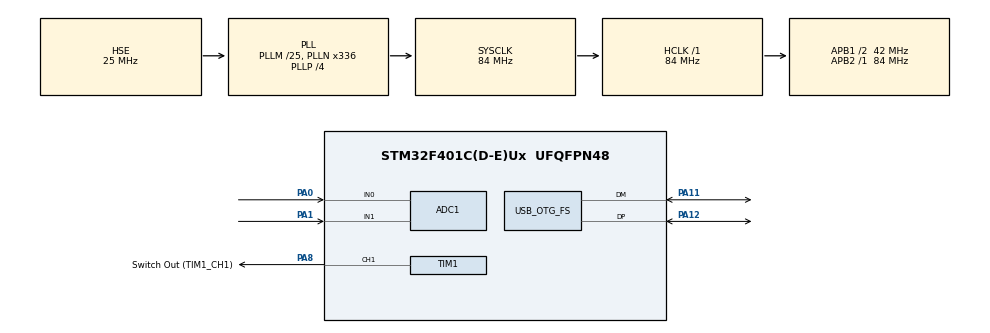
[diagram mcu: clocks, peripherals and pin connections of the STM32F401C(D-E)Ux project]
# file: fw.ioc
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ADC1.Channel-1\#ChannelRegularConversion=ADC_CHANNEL_0
ADC1.Channel-5\#ChannelRegularConversion=ADC_CHANNEL_1
ADC1.ContinuousConvMode=DISABLE
ADC1.DMAContinuousRequests=ENABLE
ADC1.DiscontinuousConvMode=DISABLE
ADC1.EOCSelection=ADC_EOC_SINGLE_CONV
ADC1.ExternalTrigConv=ADC_EXTERNALTRIGCONV_T1_CC3
ADC1.InjNumberOfConversion=0
ADC1.NbrOfConversion=2
ADC1.NbrOfConversionFlag=1
ADC1.Rank-1\#ChannelRegularConversion=1
ADC1.Rank-5\#ChannelRegularConversion=2
ADC1.SamplingTime-1\#ChannelRegularConversion=ADC_SAMPLETIME_3CYCLES
ADC1.SamplingTime-5\#ChannelRegularConversion=ADC_SAMPLETIME_3CYCLES
ADC1.master=1
Dma.ADC1.0.Direction=DMA_PERIPH_TO_MEMORY
Dma.ADC1.0.FIFOMode=DMA_FIFOMODE_DISABLE
Dma.ADC1.0.Instance=DMA2_Stream0
Dma.ADC1.0.MemDataAlignment=DMA_MDATAALIGN_HALFWORD
Dma.ADC1.0.MemInc=DMA_MINC_ENABLE
Dma.ADC1.0.Mode=DMA_CIRCULAR
Dma.ADC1.0.PeriphDataAlignment=DMA_PDATAALIGN_HALFWORD
Dma.ADC1.0.PeriphInc=DMA_PINC_DISABLE
Dma.ADC1.0.Priority=DMA_PRIORITY_LOW
Dma.Request0=ADC1
Mcu.Family=STM32F4
Mcu.Name=STM32F401C(D-E)Ux
Mcu.Package=UFQFPN48
NVIC.DMA2_Stream0_IRQn=true\:0\:0\:false\:false\:true\:false\:true\:true
NVIC.OTG_FS_IRQn=true\:0\:0\:false\:false\:true\:false\:true\:true
NVIC.PriorityGroup=NVIC_PRIORITYGROUP_4
NVIC.TIM1_BRK_TIM9_IRQn=true\:0\:0\:false\:false\:true\:true\:false\:true
NVIC.TIM1_CC_IRQn=true\:0\:0\:false\:false\:true\:true\:false\:true
NVIC.TIM1_UP_TIM10_IRQn=true\:0\:0\:false\:false\:true\:true\:false\:true
PA0-WKUP.Signal=ADCx_IN0
PA1.Signal=ADCx_IN1
PA11.Mode=Device_Only
PA11.Signal=USB_OTG_FS_DM
PA12.Mode=Device_Only
PA12.Signal=USB_OTG_FS_DP
PA8.GPIO_Label=Switch Out (TIM1_CH1)
PA8.GPIO_Speed=GPIO_SPEED_FREQ_HIGH
PA8.Signal=S_TIM1_CH1
PC14-OSC32_IN.Mode=LSE-External-Oscillator
PC14-OSC32_IN.Signal=RCC_OSC32_IN
PC15-OSC32_OUT.Mode=LSE-External-Oscillator
PC15-OSC32_OUT.Signal=RCC_OSC32_OUT
PH0\ -\ OSC_IN.Mode=HSE-External-Oscillator
PH0\ -\ OSC_IN.Signal=RCC_OSC_IN
PH1\ -\ OSC_OUT.Mode=HSE-External-Oscillator
PH1\ -\ OSC_OUT.Signal=RCC_OSC_OUT
ProjectManager.HeapSize=0x200
ProjectManager.StackSize=0x400
ProjectManager.TargetToolchain=EWARM V8.50
RCC.48MHZClocksFreq_Value=48000000
RCC.AHBFreq_Value=84000000
RCC.APB1CLKDivider=RCC_HCLK_DIV2
RCC.APB1Freq_Value=42000000
RCC.APB1TimFreq_Value=84000000
RCC.APB2Freq_Value=84000000
RCC.APB2TimFreq_Value=84000000
RCC.CortexFreq_Value=84000000
RCC.HCLKFreq_Value=84000000
RCC.HSE_VALUE=25000000
RCC.HSI_VALUE=16000000
RCC.PLLM=25
RCC.PLLN=336
RCC.PLLP=RCC_PLLP_DIV4
RCC.PLLQ=7
RCC.SYSCLKFreq_VALUE=84000000
RCC.SYSCLKSource=RCC_SYSCLKSOURCE_PLLCLK
RCC.VCOOutputFreq_Value=336000000
SH.ADCx_IN0.0=ADC1_IN0,IN0
SH.ADCx_IN1.0=ADC1_IN1,IN1
SH.S_TIM1_CH1.0=TIM1_CH1,PWM Generation1 CH1
TIM1.AutoReloadPreload=TIM_AUTORELOAD_PRELOAD_ENABLE
TIM1.Channel-Output\ Compare3\ No\ Output=TIM_CHANNEL_3
TIM1.Channel-PWM\ Generation1\ CH1=TIM_CHANNEL_1
TIM1.OC3Preload=ENABLE
TIM1.OCIdleState_1=TIM_OCIDLESTATE_RESET
TIM1.OCMode_3=TIM_OCMODE_TOGGLE
TIM1.Pulse-PWM\ Generation1\ CH1=30000
TIM1.TIM_MasterOutputTrigger=TIM_TRGO_OC4REF
TIM9.Period=8400
USB_DEVICE.APP_RX_DATA_SIZE-CDC_FS=64
USB_DEVICE.APP_TX_DATA_SIZE-CDC_FS=64
USB_DEVICE.CLASS_NAME_FS=CDC
USB_DEVICE.USBD_SELF_POWERED-CDC_FS=0
USB_DEVICE.VirtualMode-CDC_FS=Cdc
USB_DEVICE.VirtualModeFS=Cdc_FS
USB_OTG_FS.VirtualMode=Device_Only
VP_TIM1_VS_ClockSourceINT.Mode=Internal
VP_TIM1_VS_no_output3.Mode=Output Compare3 No Output
VP_TIM9_VS_ClockSourceINT.Mode=Internal
VP_USB_DEVICE_VS_USB_DEVICE_CDC_FS.Mode=CDC_FS
board=custom

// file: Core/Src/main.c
/* USER CODE BEGIN Header */
/**
 ******************************************************************************
 * @file           : main.c
 * @brief          : Main program body
 ******************************************************************************
 * @attention
 *
 * Copyright (c) 2023 STMicroelectronics.
 * All rights reserved.
 *
 * This software is licensed under terms that can be found in the LICENSE file
 * in the root directory of this software component.
 * If no LICENSE file comes with this software, it is provided AS-IS.
 *
 ******************************************************************************
 */
/* USER CODE END Header */
#include "main.h"
#include "usb_device.h"

/* USER CODE BEGIN Includes */
#include "usbd_cdc_if.h"
#include "control_main.h"
/* USER CODE END Includes */

ADC_HandleTypeDef hadc1;
DMA_HandleTypeDef hdma_adc1;

TIM_HandleTypeDef htim1;
TIM_HandleTypeDef htim9;

void SystemClock_Config(void);
static void MX_GPIO_Init(void);
static void MX_DMA_Init(void);
static void MX_TIM1_Init(void);
static void MX_ADC1_Init(void);
static void MX_TIM9_Init(void);

int main(void)
{

  /* MCU Configuration--------------------------------------------------------*/

  /* Reset of all peripherals, Initializes the Flash interface and the Systick. */
  HAL_Init();

  /* Configure the system clock */
  SystemClock_Config();

  /* Initialize all configured peripherals */
  MX_GPIO_Init();
  MX_DMA_Init();
  MX_TIM1_Init();
  MX_USB_DEVICE_Init();
  MX_ADC1_Init();
  MX_TIM9_Init();
  /* USER CODE BEGIN 2 */

  // HAL_TIM_Base_Start(&htim1);
  // HAL_TIM_PWM_Start(&htim1, TIM_CHANNEL_1);

  // TIM1->DIER |= TIM_IT_UPDATE;
  /* USER CODE END 2 */

  /* Infinite loop */
  while (1)
  {

    /* USER CODE BEGIN 3 */
    // uint8_t HiMsg[] = "hello\r\n";
    // CDC_Transmit_FS(HiMsg, strlen((char *)HiMsg));
    // TIM1->CCR1 += 5000;
    // HAL_Delay(2000);
    controlMain();
  }
  /* USER CODE END 3 */
}

void SystemClock_Config(void)
{
  RCC_OscInitTypeDef RCC_OscInitStruct = {0};
  RCC_ClkInitTypeDef RCC_ClkInitStruct = {0};

  /** Configure the main internal regulator output voltage
   */
  __HAL_RCC_PWR_CLK_ENABLE();
  __HAL_PWR_VOLTAGESCALING_CONFIG(PWR_REGULATOR_VOLTAGE_SCALE2);

  /** Initializes the RCC Oscillators according to the specified parameters
   * in the RCC_OscInitTypeDef structure.
   */
  RCC_OscInitStruct.OscillatorType = RCC_OSCILLATORTYPE_HSE;
  RCC_OscInitStruct.HSEState = RCC_HSE_ON;
  RCC_OscInitStruct.PLL.PLLState = RCC_PLL_ON;
  RCC_OscInitStruct.PLL.PLLSource = RCC_PLLSOURCE_HSE;
  RCC_OscInitStruct.PLL.PLLM = 25;
  RCC_OscInitStruct.PLL.PLLN = 336;
  RCC_OscInitStruct.PLL.PLLP = RCC_PLLP_DIV4;
  RCC_OscInitStruct.PLL.PLLQ = 7;
  if (HAL_RCC_OscConfig(&RCC_OscInitStruct) != HAL_OK)
  {
    Error_Handler();
  }

  /** Initializes the CPU, AHB and APB buses clocks
   */
  RCC_ClkInitStruct.ClockType = RCC_CLOCKTYPE_HCLK | RCC_CLOCKTYPE_SYSCLK | RCC_CLOCKTYPE_PCLK1 | RCC_CLOCKTYPE_PCLK2;
  RCC_ClkInitStruct.SYSCLKSource = RCC_SYSCLKSOURCE_PLLCLK;
  RCC_ClkInitStruct.AHBCLKDivider = RCC_SYSCLK_DIV1;
  RCC_ClkInitStruct.APB1CLKDivider = RCC_HCLK_DIV2;
  RCC_ClkInitStruct.APB2CLKDivider = RCC_HCLK_DIV1;

  if (HAL_RCC_ClockConfig(&RCC_ClkInitStruct, FLASH_LATENCY_2) != HAL_OK)
  {
    Error_Handler();
  }
}

static void MX_ADC1_Init(void)
{

  ADC_ChannelConfTypeDef sConfig = {0};

  /** Configure the global features of the ADC (Clock, Resolution, Data Alignment and number of conversion)
   */
  hadc1.Instance = ADC1;
  hadc1.Init.ClockPrescaler = ADC_CLOCK_SYNC_PCLK_DIV4;
  hadc1.Init.Resolution = ADC_RESOLUTION_12B;
  hadc1.Init.ScanConvMode = ENABLE;
  hadc1.Init.ContinuousConvMode = DISABLE;
  hadc1.Init.DiscontinuousConvMode = DISABLE;
  hadc1.Init.ExternalTrigConvEdge = ADC_EXTERNALTRIGCONVEDGE_RISING;
  hadc1.Init.ExternalTrigConv = ADC_EXTERNALTRIGCONV_T1_CC3;
  hadc1.Init.DataAlign = ADC_DATAALIGN_RIGHT;
  hadc1.Init.NbrOfConversion = 2;
  hadc1.Init.DMAContinuousRequests = ENABLE;
  hadc1.Init.EOCSelection = ADC_EOC_SINGLE_CONV;
  if (HAL_ADC_Init(&hadc1) != HAL_OK)
  {
    Error_Handler();
  }

  /** Configure for the selected ADC regular channel its corresponding rank in the sequencer and its sample time.
   */
  sConfig.Channel = ADC_CHANNEL_0;
  sConfig.Rank = 1;
  sConfig.SamplingTime = ADC_SAMPLETIME_480CYCLES;
  // sConfig.SamplingTime = ADC_SAMPLETIME_3CYCLES;
  if (HAL_ADC_ConfigChannel(&hadc1, &sConfig) != HAL_OK)
  {
    Error_Handler();
  }

  /** Configure for the selected ADC regular channel its corresponding rank in the sequencer and its sample time.
   */
  sConfig.Channel = ADC_CHANNEL_1;
  sConfig.Rank = 2;
  if (HAL_ADC_ConfigChannel(&hadc1, &sConfig) != HAL_OK)
  {
    Error_Handler();
  }
}

static void MX_TIM1_Init(void)
{

  TIM_ClockConfigTypeDef sClockSourceConfig = {0};
  TIM_MasterConfigTypeDef sMasterConfig = {0};
  TIM_OC_InitTypeDef sConfigOC = {0};
  TIM_BreakDeadTimeConfigTypeDef sBreakDeadTimeConfig = {0};

  htim1.Instance = TIM1;
  htim1.Init.Prescaler = 0;
  htim1.Init.CounterMode = TIM_COUNTERMODE_UP;
  htim1.Init.Period = 65535;
  htim1.Init.ClockDivision = TIM_CLOCKDIVISION_DIV1;
  htim1.Init.RepetitionCounter = 0;
  htim1.Init.AutoReloadPreload = TIM_AUTORELOAD_PRELOAD_ENABLE;
  if (HAL_TIM_Base_Init(&htim1) != HAL_OK)
  {
    Error_Handler();
  }
  sClockSourceConfig.ClockSource = TIM_CLOCKSOURCE_INTERNAL;
  if (HAL_TIM_ConfigClockSource(&htim1, &sClockSourceConfig) != HAL_OK)
  {
    Error_Handler();
  }
  if (HAL_TIM_PWM_Init(&htim1) != HAL_OK)
  {
    Error_Handler();
  }
  if (HAL_TIM_OC_Init(&htim1) != HAL_OK)
  {
    Error_Handler();
  }
  sMasterConfig.MasterOutputTrigger = TIM_TRGO_OC4REF;
  sMasterConfig.MasterSlaveMode = TIM_MASTERSLAVEMODE_DISABLE;
  if (HAL_TIMEx_MasterConfigSynchronization(&htim1, &sMasterConfig) != HAL_OK)
  {
    Error_Handler();
  }
  sConfigOC.OCMode = TIM_OCMODE_PWM1;
  sConfigOC.Pulse = 30000;
  sConfigOC.OCPolarity = TIM_OCPOLARITY_HIGH;
  sConfigOC.OCNPolarity = TIM_OCNPOLARITY_HIGH;
  sConfigOC.OCFastMode = TIM_OCFAST_DISABLE;
  sConfigOC.OCIdleState = TIM_OCIDLESTATE_RESET;
  sConfigOC.OCNIdleState = TIM_OCNIDLESTATE_RESET;
  if (HAL_TIM_PWM_ConfigChannel(&htim1, &sConfigOC, TIM_CHANNEL_1) != HAL_OK)
  {
    Error_Handler();
  }
  sConfigOC.OCMode = TIM_OCMODE_TOGGLE;
  sConfigOC.Pulse = 0;
  if (HAL_TIM_OC_ConfigChannel(&htim1, &sConfigOC, TIM_CHANNEL_3) != HAL_OK)
  {
    Error_Handler();
  }
  __HAL_TIM_ENABLE_OCxPRELOAD(&htim1, TIM_CHANNEL_3);
  sBreakDeadTimeConfig.OffStateRunMode = TIM_OSSR_DISABLE;
  sBreakDeadTimeConfig.OffStateIDLEMode = TIM_OSSI_DISABLE;
  sBreakDeadTimeConfig.LockLevel = TIM_LOCKLEVEL_OFF;
  sBreakDeadTimeConfig.DeadTime = 0;
  sBreakDeadTimeConfig.BreakState = TIM_BREAK_DISABLE;
  sBreakDeadTimeConfig.BreakPolarity = TIM_BREAKPOLARITY_HIGH;
  sBreakDeadTimeConfig.AutomaticOutput = TIM_AUTOMATICOUTPUT_DISABLE;
  if (HAL_TIMEx_ConfigBreakDeadTime(&htim1, &sBreakDeadTimeConfig) != HAL_OK)
  {
    Error_Handler();
  }
  HAL_TIM_MspPostInit(&htim1);
}

static void MX_TIM9_Init(void)
{

  TIM_ClockConfigTypeDef sClockSourceConfig = {0};

  htim9.Instance = TIM9;
  htim9.Init.Prescaler = 0;
  htim9.Init.CounterMode = TIM_COUNTERMODE_UP;
  htim9.Init.Period = 8400;
  htim9.Init.ClockDivision = TIM_CLOCKDIVISION_DIV1;
  htim9.Init.AutoReloadPreload = TIM_AUTORELOAD_PRELOAD_DISABLE;
  if (HAL_TIM_Base_Init(&htim9) != HAL_OK)
  {
    Error_Handler();
  }
  sClockSourceConfig.ClockSource = TIM_CLOCKSOURCE_INTERNAL;
  if (HAL_TIM_ConfigClockSource(&htim9, &sClockSourceConfig) != HAL_OK)
  {
    Error_Handler();
  }
}

static void MX_DMA_Init(void)
{

  /* DMA controller clock enable */
  __HAL_RCC_DMA2_CLK_ENABLE();

  /* DMA interrupt init */
  /* DMA2_Stream0_IRQn interrupt configuration */
  HAL_NVIC_SetPriority(DMA2_Stream0_IRQn, 0, 0);
  HAL_NVIC_EnableIRQ(DMA2_Stream0_IRQn);
}

static void MX_GPIO_Init(void)
{

  /* GPIO Ports Clock Enable */
  __HAL_RCC_GPIOC_CLK_ENABLE();
  __HAL_RCC_GPIOH_CLK_ENABLE();
  __HAL_RCC_GPIOA_CLK_ENABLE();
}

void Error_Handler(void)
{
  __disable_irq();
  while (1)
  {
  }
}
